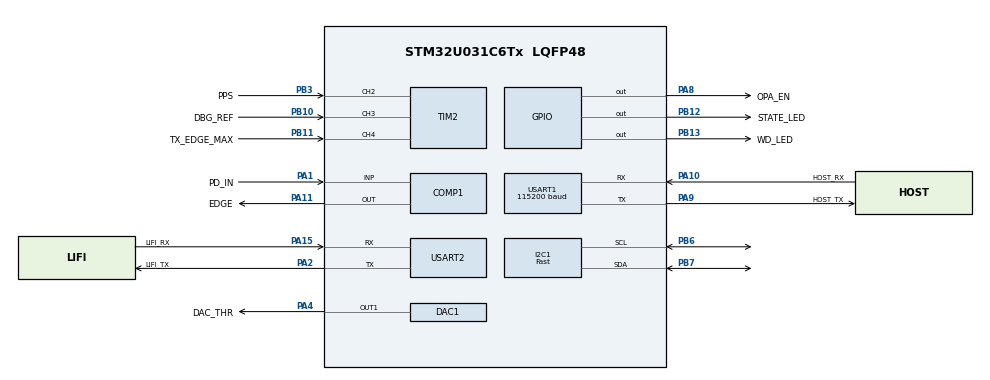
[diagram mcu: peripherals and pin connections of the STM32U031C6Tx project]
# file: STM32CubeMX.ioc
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ADC1.Channel-0\#ChannelRegularConversion=ADC_CHANNEL_5
ADC1.NbrOfConversionFlag=1
ADC1.Rank-0\#ChannelRegularConversion=1
ADC1.RankArg-0\#ChannelRegularConversion=ADC_REGULAR_RANK_1
ADC1.SamplingTime-0\#ChannelRegularConversion=ADC_SAMPLINGTIME_COMMON_1
ADC1.SamplingTimeCommon1=ADC_SAMPLETIME_39CYCLES_5
ADC1.SelectedChannel=ADC_CHANNEL_5
ADC1.master=1
COMP1.Hysteresis=COMP_HYSTERESIS_LOW
Dma.Request0=USART2_TX
Dma.Request1=USART1_TX
Dma.Request2=USART1_RX
Dma.Request3=USART2_RX
Dma.USART1_RX.2.Direction=DMA_PERIPH_TO_MEMORY
Dma.USART1_RX.2.EventEnable=DISABLE
Dma.USART1_RX.2.Instance=DMA1_Channel3
Dma.USART1_RX.2.MemDataAlignment=DMA_MDATAALIGN_BYTE
Dma.USART1_RX.2.MemInc=DMA_MINC_ENABLE
Dma.USART1_RX.2.Mode=DMA_CIRCULAR
Dma.USART1_RX.2.PeriphDataAlignment=DMA_PDATAALIGN_BYTE
Dma.USART1_RX.2.PeriphInc=DMA_PINC_DISABLE
Dma.USART1_RX.2.Polarity=HAL_DMAMUX_REQ_GEN_RISING
Dma.USART1_RX.2.Priority=DMA_PRIORITY_LOW
Dma.USART1_RX.2.RequestNumber=1
Dma.USART1_RX.2.SignalID=NONE
Dma.USART1_RX.2.SyncEnable=DISABLE
Dma.USART1_RX.2.SyncPolarity=HAL_DMAMUX_SYNC_NO_EVENT
Dma.USART1_RX.2.SyncRequestNumber=1
Dma.USART1_RX.2.SyncSignalID=NONE
Dma.USART1_TX.1.Direction=DMA_MEMORY_TO_PERIPH
Dma.USART1_TX.1.EventEnable=DISABLE
Dma.USART1_TX.1.Instance=DMA1_Channel2
Dma.USART1_TX.1.MemDataAlignment=DMA_MDATAALIGN_BYTE
Dma.USART1_TX.1.MemInc=DMA_MINC_ENABLE
Dma.USART1_TX.1.Mode=DMA_NORMAL
Dma.USART1_TX.1.PeriphDataAlignment=DMA_PDATAALIGN_BYTE
Dma.USART1_TX.1.PeriphInc=DMA_PINC_DISABLE
Dma.USART1_TX.1.Polarity=HAL_DMAMUX_REQ_GEN_RISING
Dma.USART1_TX.1.Priority=DMA_PRIORITY_LOW
Dma.USART1_TX.1.RequestNumber=1
Dma.USART1_TX.1.SignalID=NONE
Dma.USART1_TX.1.SyncEnable=DISABLE
Dma.USART1_TX.1.SyncPolarity=HAL_DMAMUX_SYNC_NO_EVENT
Dma.USART1_TX.1.SyncRequestNumber=1
Dma.USART1_TX.1.SyncSignalID=NONE
Dma.USART2_RX.3.Direction=DMA_PERIPH_TO_MEMORY
Dma.USART2_RX.3.EventEnable=DISABLE
Dma.USART2_RX.3.Instance=DMA1_Channel4
Dma.USART2_RX.3.MemDataAlignment=DMA_MDATAALIGN_BYTE
Dma.USART2_RX.3.MemInc=DMA_MINC_ENABLE
Dma.USART2_RX.3.Mode=DMA_CIRCULAR
Dma.USART2_RX.3.PeriphDataAlignment=DMA_PDATAALIGN_BYTE
Dma.USART2_RX.3.PeriphInc=DMA_PINC_DISABLE
Dma.USART2_RX.3.Polarity=HAL_DMAMUX_REQ_GEN_RISING
Dma.USART2_RX.3.Priority=DMA_PRIORITY_LOW
Dma.USART2_RX.3.RequestNumber=1
Dma.USART2_RX.3.SignalID=NONE
Dma.USART2_RX.3.SyncEnable=DISABLE
Dma.USART2_RX.3.SyncPolarity=HAL_DMAMUX_SYNC_NO_EVENT
Dma.USART2_RX.3.SyncRequestNumber=1
Dma.USART2_RX.3.SyncSignalID=NONE
Dma.USART2_TX.0.Direction=DMA_MEMORY_TO_PERIPH
Dma.USART2_TX.0.EventEnable=DISABLE
Dma.USART2_TX.0.Instance=DMA1_Channel1
Dma.USART2_TX.0.MemDataAlignment=DMA_MDATAALIGN_BYTE
Dma.USART2_TX.0.MemInc=DMA_MINC_ENABLE
Dma.USART2_TX.0.Mode=DMA_NORMAL
Dma.USART2_TX.0.PeriphDataAlignment=DMA_PDATAALIGN_BYTE
Dma.USART2_TX.0.PeriphInc=DMA_PINC_DISABLE
Dma.USART2_TX.0.Polarity=HAL_DMAMUX_REQ_GEN_RISING
Dma.USART2_TX.0.Priority=DMA_PRIORITY_LOW
Dma.USART2_TX.0.RequestNumber=1
Dma.USART2_TX.0.SignalID=NONE
Dma.USART2_TX.0.SyncEnable=DISABLE
Dma.USART2_TX.0.SyncPolarity=HAL_DMAMUX_SYNC_NO_EVENT
Dma.USART2_TX.0.SyncRequestNumber=1
Dma.USART2_TX.0.SyncSignalID=NONE
I2C1.I2C_Speed_Mode=I2C_Fast
I2C1.Timing=0x00200C28
Mcu.Family=STM32U0
Mcu.Name=STM32U031C6Tx
Mcu.Package=LQFP48
NVIC.DMA1_Ch4_7_DMAMUX_OVR_IRQn=true\:0\:0\:false\:false\:false\:false\:true\:true
NVIC.DMA1_Channel1_IRQn=true\:0\:0\:false\:false\:false\:false\:true\:true
NVIC.DMA1_Channel2_3_IRQn=true\:0\:0\:false\:false\:false\:false\:true\:true
NVIC.PriorityGroup=NVIC_PRIORITYGROUP_2
NVIC.TIM2_IRQn=true\:0\:0\:false\:false\:false\:true\:true\:true
NVIC.USART1_IRQn=true\:0\:0\:false\:false\:false\:true\:true\:true
NVIC.USART2_LPUART2_IRQn=true\:0\:0\:false\:false\:false\:true\:true\:true
PA1.GPIO_Label=PD_IN
PA1.Signal=SharedAnalog_PA1
PA10.GPIO_Label=HOST_RX
PA10.Mode=Asynchronous
PA10.Signal=USART1_RX
PA11\ [PA9].GPIO_Label=EDGE
PA11\ [PA9].Mode=ExternalOutput
PA11\ [PA9].Signal=COMP1_OUT
PA13\ (SWDIO).GPIO_Label=SWDIO
PA13\ (SWDIO).Mode=Serial_Wire
PA13\ (SWDIO).Signal=DEBUG_JTMS-SWDIO
PA14\ (SWCLK).GPIO_Label=SWCLK
PA14\ (SWCLK).Mode=Serial_Wire
PA14\ (SWCLK).Signal=DEBUG_JTCK-SWCLK
PA15.GPIO_Label=LIFI_RX
PA15.Mode=Asynchronous
PA15.Signal=USART2_RX
PA2.GPIO_Label=LIFI_TX
PA2.Mode=Asynchronous
PA2.Signal=USART2_TX
PA4.GPIO_Label=DAC_THR
PA4.Signal=COMP_DAC11_group
PA8.GPIO_Label=OPA_EN
PA8.PinState=GPIO_PIN_RESET
PA8.Signal=GPIO_Output
PA9.GPIO_Label=HOST_TX
PA9.Mode=Asynchronous
PA9.Signal=USART1_TX
PB10.GPIO_Label=DBG_REF
PB10.Signal=S_TIM2_CH3
PB11.GPIO_Label=TX_EDGE_MAX
PB11.Signal=S_TIM2_CH4
PB12.GPIO_Label=STATE_LED
PB12.Signal=GPIO_Output
PB13.GPIO_Label=WD_LED
PB13.Signal=GPIO_Output
PB3.GPIO_Label=PPS
PB3.Signal=S_TIM2_CH2
PB6.Mode=I2C
PB6.Signal=I2C1_SCL
PB7.Mode=I2C
PB7.Signal=I2C1_SDA
PF0-OSC_IN.GPIO_Label=OSC_IN
PF0-OSC_IN.Mode=HSE-External-Clock-Source
PF0-OSC_IN.Signal=RCC_OSC_IN
PF1-OSC_OUT.GPIO_Label=OSC_EN
PF1-OSC_OUT.Mode=OSC enable
PF1-OSC_OUT.Signal=RCC_OSC_EN
ProjectManager.HeapSize=0x0
ProjectManager.StackSize=0x400
ProjectManager.TargetToolchain=STM32CubeIDE
RCC.ADCFreq_Value=24000000
RCC.AHBFreq_Value=24000000
RCC.CortexFreq_Value=24000000
RCC.HCLKFreq_Value=24000000
RCC.HSE_VALUE=24000000
RCC.HSI48_VALUE=48000000
RCC.HSI_VALUE=16000000
RCC.LSE_VALUE=32768
RCC.MSI_VALUE=4000000
RCC.SYSCLKFreq_VALUE=24000000
RCC.SYSCLKSource=RCC_SYSCLKSOURCE_HSE
RCC.VCOOutputFreq_Value=64000000
SH.COMP_DAC11_group.0=DAC1_OUT1,DAC_OUT1_ExtAndInt
SH.S_TIM2_CH2.0=TIM2_CH2,Input_Capture2_from_TI2
SH.S_TIM2_CH3.0=TIM2_CH3,Input_Capture3_from_TI3
SH.S_TIM2_CH4.0=TIM2_CH4,Input_Capture4_from_TI4
SH.SharedAnalog_PA1.0=COMP1_INP,INP
SH.SharedAnalog_PA1.1=ADC1_IN5,IN5
TIM2.Channel-Input_Capture1_from_TI1_REMAP_TIM2=TIM_CHANNEL_1
TIM2.Channel-Input_Capture2_from_TI2=TIM_CHANNEL_2
TIM2.Channel-Input_Capture3_from_TI3=TIM_CHANNEL_3
TIM2.Channel-Input_Capture4_from_TI4=TIM_CHANNEL_4
TIM2.ICPolarity_CH1=TIM_INPUTCHANNELPOLARITY_BOTHEDGE
TIM2.ICPolarity_CH4=TIM_INPUTCHANNELPOLARITY_BOTHEDGE
USART1.BaudRate=115200
USART1.VirtualMode-Asynchronous=VM_ASYNC
USART2.RxPinLevelInvertParam=ADVFEATURE_RXINV_ENABLE
USART2.TxPinLevelInvertParam=ADVFEATURE_TXINV_ENABLE
USART2.VirtualMode-Asynchronous=VM_ASYNC
VP_COMP1_VS_DACOUT1.Mode=INM_DACOUT1
VP_PWR_VS_SECSignals.Mode=Security/Privilege
VP_TIM2_VS_ClockSourceINT.Mode=Internal
VP_TIM2_VS_NoInput1.Mode=Input_Capture1_from_TI1_REMAP_TIM2
board=custom

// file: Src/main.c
/* USER CODE BEGIN Header */
/**
  ******************************************************************************
  * @file           : main.c
  * @brief          : Main program body
  ******************************************************************************
  * @attention
  *
  * Copyright (c) 2026 STMicroelectronics.
  * All rights reserved.
  *
  * This software is licensed under terms that can be found in the LICENSE file
  * in the root directory of this software component.
  * If no LICENSE file comes with this software, it is provided AS-IS.
  *
  ******************************************************************************
  */
/* USER CODE END Header */
#include "main.h"

void SystemClock_Config(void);
static void MX_GPIO_Init(void);
static void MX_DMA_Init(void);
static void MX_USART1_UART_Init(void);
static void MX_COMP1_Init(void);
static void MX_USART2_UART_Init(void);
static void MX_ADC1_Init(void);
static void MX_DAC1_Init(void);
static void MX_TIM2_Init(void);
static void MX_I2C1_Init(void);
/* USER CODE BEGIN PFP */
extern int app_main(void);

/* USER CODE END PFP */

int main(void)
{

  /* MCU Configuration--------------------------------------------------------*/

  /* Reset of all peripherals, Initializes the Flash interface and the Systick. */
  LL_APB1_GRP1_EnableClock(LL_APB1_GRP1_PERIPH_PWR);
  LL_APB1_GRP2_EnableClock(LL_APB1_GRP2_PERIPH_SYSCFG);

  /* System interrupt init*/
  NVIC_SetPriorityGrouping(NVIC_PRIORITYGROUP_2);

  /* SysTick_IRQn interrupt configuration */
  NVIC_SetPriority(SysTick_IRQn, NVIC_EncodePriority(NVIC_GetPriorityGrouping(),3, 0));

  /* Initialize all configured peripherals */
  MX_GPIO_Init();
  MX_DMA_Init();
  MX_USART1_UART_Init();
  MX_COMP1_Init();
  MX_USART2_UART_Init();
  MX_ADC1_Init();
  MX_DAC1_Init();
  MX_TIM2_Init();
  MX_I2C1_Init();
  /* USER CODE BEGIN 2 */
  app_main();

  /* USER CODE END 2 */

  /* Infinite loop */
  while (1)
  {

  }
}

void SystemClock_Config(void)
{
  LL_FLASH_SetLatency(LL_FLASH_LATENCY_0);
  while(LL_FLASH_GetLatency() != LL_FLASH_LATENCY_0)
  {
  }

  LL_PWR_SetRegulVoltageScaling(LL_PWR_REGU_VOLTAGE_SCALE1);
  while (LL_PWR_IsActiveFlag_VOS() != 0)
  {
  }
  LL_RCC_HSE_EnableBypass();
  LL_RCC_HSE_Enable();

   /* Wait till HSE is ready */
  while(LL_RCC_HSE_IsReady() != 1)
  {
  }

  LL_RCC_SetSysClkSource(LL_RCC_SYS_CLKSOURCE_HSE);

   /* Wait till System clock is ready */
  while(LL_RCC_GetSysClkSource() != LL_RCC_SYS_CLKSOURCE_STATUS_HSE)
  {
  }

  LL_RCC_SetAHBPrescaler(LL_RCC_SYSCLK_DIV_1);
  LL_RCC_SetAPB1Prescaler(LL_RCC_APB1_DIV_1);

  LL_Init1msTick(24000000);

  LL_SetSystemCoreClock(24000000);
}

static void MX_ADC1_Init(void)
{

  LL_ADC_InitTypeDef ADC_InitStruct = {0};
  LL_ADC_REG_InitTypeDef ADC_REG_InitStruct = {0};

  LL_GPIO_InitTypeDef GPIO_InitStruct = {0};

  LL_RCC_SetADCClockSource(LL_RCC_ADC_CLKSOURCE_SYSCLK);

  /* Peripheral clock enable */
  LL_APB1_GRP2_EnableClock(LL_APB1_GRP2_PERIPH_ADC);

  LL_IOP_GRP1_EnableClock(LL_IOP_GRP1_PERIPH_GPIOA);
  /**ADC1 GPIO Configuration
  PA1   ------> ADC1_IN5
  */
  GPIO_InitStruct.Pin = PD_IN_Pin;
  GPIO_InitStruct.Mode = LL_GPIO_MODE_ANALOG;
  GPIO_InitStruct.Pull = LL_GPIO_PULL_NO;
  LL_GPIO_Init(PD_IN_GPIO_Port, &GPIO_InitStruct);

  /** Configure the global features of the ADC (Clock, Resolution, Data Alignment and number of conversion)
  */

   #define ADC_CHANNEL_CONF_RDY_TIMEOUT_MS ( 1U)
   #if (USE_TIMEOUT == 1)
   uint32_t Timeout ; /* Variable used for Timeout management */
   #endif /* USE_TIMEOUT */

  ADC_InitStruct.Clock = LL_ADC_CLOCK_SYNC_PCLK_DIV1;
  ADC_InitStruct.Resolution = LL_ADC_RESOLUTION_12B;
  ADC_InitStruct.DataAlignment = LL_ADC_DATA_ALIGN_RIGHT;
  ADC_InitStruct.LowPowerMode = LL_ADC_LP_MODE_NONE;
  LL_ADC_Init(ADC1, &ADC_InitStruct);
  LL_ADC_REG_SetSequencerConfigurable(ADC1, LL_ADC_REG_SEQ_CONFIGURABLE);

   /* Poll for ADC channel configuration ready */
   #if (USE_TIMEOUT == 1)
   Timeout = ADC_CHANNEL_CONF_RDY_TIMEOUT_MS;
   #endif /* USE_TIMEOUT */
   while (LL_ADC_IsActiveFlag_CCRDY(ADC1) == 0)
     {
   #if (USE_TIMEOUT == 1)
   /* Check Systick counter flag to decrement the time-out value */
   if (LL_SYSTICK_IsActiveCounterFlag())
     {
   if(Timeout-- == 0)
         {
   Error_Handler();
         }
     }
   #endif /* USE_TIMEOUT */
     }
   /* Clear flag ADC channel configuration ready */
   LL_ADC_ClearFlag_CCRDY(ADC1);
  ADC_REG_InitStruct.TriggerSource = LL_ADC_REG_TRIG_SOFTWARE;
  ADC_REG_InitStruct.SequencerLength = LL_ADC_REG_SEQ_SCAN_DISABLE;
  ADC_REG_InitStruct.SequencerDiscont = LL_ADC_REG_SEQ_DISCONT_DISABLE;
  ADC_REG_InitStruct.ContinuousMode = LL_ADC_REG_CONV_SINGLE;
  ADC_REG_InitStruct.DMATransfer = LL_ADC_REG_DMA_TRANSFER_NONE;
  ADC_REG_InitStruct.Overrun = LL_ADC_REG_OVR_DATA_PRESERVED;
  LL_ADC_REG_Init(ADC1, &ADC_REG_InitStruct);
  LL_ADC_SetOverSamplingScope(ADC1, LL_ADC_OVS_DISABLE);
  LL_ADC_SetTriggerFrequencyMode(ADC1, LL_ADC_TRIGGER_FREQ_HIGH);
  LL_ADC_SetSamplingTimeCommonChannels(ADC1, LL_ADC_SAMPLINGTIME_COMMON_1, LL_ADC_SAMPLINGTIME_39CYCLES_5);
  LL_ADC_SetSamplingTimeCommonChannels(ADC1, LL_ADC_SAMPLINGTIME_COMMON_2, LL_ADC_SAMPLINGTIME_1CYCLE_5);
  LL_ADC_DisableIT_EOC(ADC1);
  LL_ADC_DisableIT_EOS(ADC1);

   /* Enable ADC internal voltage regulator */
   LL_ADC_EnableInternalRegulator(ADC1);
   /* Delay for ADC internal voltage regulator stabilization. */
   /* Compute number of CPU cycles to wait for, from delay in us. */
   /* Note: Variable divided by 2 to compensate partially */
   /* CPU processing cycles (depends on compilation optimization). */
   /* Note: If system core clock frequency is below 200kHz, wait time */
   /* is only a few CPU processing cycles. */
   uint32_t wait_loop_index;
   wait_loop_index = ((LL_ADC_DELAY_INTERNAL_REGUL_STAB_US * (SystemCoreClock / (100000 * 2))) / 10);
   while(wait_loop_index != 0)
     {
   wait_loop_index--;
     }

  /** Configure Regular Channel
  */
  LL_ADC_REG_SetSequencerRanks(ADC1, LL_ADC_REG_RANK_1, LL_ADC_CHANNEL_5);

   /* Poll for ADC channel configuration ready */
   #if (USE_TIMEOUT == 1)
   Timeout = ADC_CHANNEL_CONF_RDY_TIMEOUT_MS;
   #endif /* USE_TIMEOUT */
   while (LL_ADC_IsActiveFlag_CCRDY(ADC1) == 0)
     {
   #if (USE_TIMEOUT == 1)
   /* Check Systick counter flag to decrement the time-out value */
   if (LL_SYSTICK_IsActiveCounterFlag())
     {
   if(Timeout-- == 0)
         {
   Error_Handler();
         }
     }
   #endif /* USE_TIMEOUT */
     }
   /* Clear flag ADC channel configuration ready */
   LL_ADC_ClearFlag_CCRDY(ADC1);
  LL_ADC_SetChannelSamplingTime(ADC1, LL_ADC_CHANNEL_5, LL_ADC_SAMPLINGTIME_COMMON_1);

}

static void MX_COMP1_Init(void)
{

  LL_COMP_InitTypeDef COMP_InitStruct = {0};

  LL_GPIO_InitTypeDef GPIO_InitStruct = {0};

  /* Peripheral clock enable */
  LL_APB1_GRP2_EnableClock(LL_APB1_GRP2_PERIPH_COMP);

  LL_IOP_GRP1_EnableClock(LL_IOP_GRP1_PERIPH_GPIOA);
  /**COMP1 GPIO Configuration
  PA1   ------> COMP1_INP
  PA11 [PA9]   ------> COMP1_OUT
  */
  GPIO_InitStruct.Pin = PD_IN_Pin;
  GPIO_InitStruct.Mode = LL_GPIO_MODE_ANALOG;
  GPIO_InitStruct.Pull = LL_GPIO_PULL_NO;
  LL_GPIO_Init(PD_IN_GPIO_Port, &GPIO_InitStruct);

  GPIO_InitStruct.Pin = EDGE_Pin;
  GPIO_InitStruct.Mode = LL_GPIO_MODE_ALTERNATE;
  GPIO_InitStruct.Speed = LL_GPIO_SPEED_FREQ_LOW;
  GPIO_InitStruct.OutputType = LL_GPIO_OUTPUT_PUSHPULL;
  GPIO_InitStruct.Pull = LL_GPIO_PULL_NO;
  GPIO_InitStruct.Alternate = LL_GPIO_AF_12;
  LL_GPIO_Init(EDGE_GPIO_Port, &GPIO_InitStruct);

  COMP_InitStruct.InputPlus = LL_COMP_INPUT_PLUS_IO3;
  COMP_InitStruct.InputMinus = LL_COMP_INPUT_MINUS_DAC1_CH1;
  COMP_InitStruct.InputHysteresis = LL_COMP_HYSTERESIS_LOW;
  COMP_InitStruct.OutputPolarity = LL_COMP_OUTPUTPOL_NONINVERTED;
  COMP_InitStruct.OutputBlankingSource = LL_COMP_BLANKINGSRC_NONE;
  LL_COMP_Init(COMP1, &COMP_InitStruct);
  LL_COMP_SetPowerMode(COMP1, LL_COMP_POWERMODE_HIGHSPEED);

  /* Wait loop initialization and execution */
  /* Note: Variable divided by 2 to compensate partially CPU processing cycles */
  __IO uint32_t wait_loop_index = 0;
  wait_loop_index = (LL_COMP_DELAY_VOLTAGE_SCALER_STAB_US * (SystemCoreClock / (1000000 * 2)));
  while(wait_loop_index != 0)
  {
    wait_loop_index--;
  }
  LL_EXTI_DisableEvent_0_31(LL_EXTI_LINE_17);
  LL_EXTI_DisableIT_0_31(LL_EXTI_LINE_17);

}

static void MX_DAC1_Init(void)
{

  LL_DAC_InitTypeDef DAC_InitStruct = {0};

  LL_GPIO_InitTypeDef GPIO_InitStruct = {0};

  /* Peripheral clock enable */
  LL_APB1_GRP1_EnableClock(LL_APB1_GRP1_PERIPH_DAC1);

  LL_IOP_GRP1_EnableClock(LL_IOP_GRP1_PERIPH_GPIOA);
  /**DAC1 GPIO Configuration
  PA4   ------> DAC1_OUT1
  */
  GPIO_InitStruct.Pin = DAC_THR_Pin;
  GPIO_InitStruct.Mode = LL_GPIO_MODE_ANALOG;
  GPIO_InitStruct.Pull = LL_GPIO_PULL_NO;
  LL_GPIO_Init(DAC_THR_GPIO_Port, &GPIO_InitStruct);

  /** DAC channel OUT1 config
  */
  DAC_InitStruct.TriggerSource = LL_DAC_TRIG_SOFTWARE;
  DAC_InitStruct.WaveAutoGeneration = LL_DAC_WAVE_AUTO_GENERATION_NONE;
  DAC_InitStruct.OutputBuffer = LL_DAC_OUTPUT_BUFFER_ENABLE;
  DAC_InitStruct.OutputConnection = LL_DAC_OUTPUT_CONNECT_INTERNAL;
  DAC_InitStruct.OutputMode = LL_DAC_OUTPUT_MODE_NORMAL;
  LL_DAC_Init(DAC1, LL_DAC_CHANNEL_1, &DAC_InitStruct);
  LL_DAC_DisableTrigger(DAC1, LL_DAC_CHANNEL_1);

}

static void MX_I2C1_Init(void)
{

  LL_I2C_InitTypeDef I2C_InitStruct = {0};

  LL_GPIO_InitTypeDef GPIO_InitStruct = {0};

  LL_RCC_SetI2CClockSource(LL_RCC_I2C1_CLKSOURCE_PCLK1);

  LL_IOP_GRP1_EnableClock(LL_IOP_GRP1_PERIPH_GPIOB);
  /**I2C1 GPIO Configuration
  PB6   ------> I2C1_SCL
  PB7   ------> I2C1_SDA
  */
  GPIO_InitStruct.Pin = LL_GPIO_PIN_6|LL_GPIO_PIN_7;
  GPIO_InitStruct.Mode = LL_GPIO_MODE_ALTERNATE;
  GPIO_InitStruct.Speed = LL_GPIO_SPEED_FREQ_LOW;
  GPIO_InitStruct.OutputType = LL_GPIO_OUTPUT_OPENDRAIN;
  GPIO_InitStruct.Pull = LL_GPIO_PULL_NO;
  GPIO_InitStruct.Alternate = LL_GPIO_AF_4;
  LL_GPIO_Init(GPIOB, &GPIO_InitStruct);

  /* Peripheral clock enable */
  LL_APB1_GRP1_EnableClock(LL_APB1_GRP1_PERIPH_I2C1);

  /** I2C Initialization
  */
  LL_I2C_EnableAutoEndMode(I2C1);
  LL_I2C_DisableOwnAddress2(I2C1);
  LL_I2C_DisableGeneralCall(I2C1);
  LL_I2C_EnableClockStretching(I2C1);
  I2C_InitStruct.Timing = 0x00200C28;
  I2C_InitStruct.AnalogFilter = LL_I2C_ANALOGFILTER_ENABLE;
  I2C_InitStruct.DigitalFilter = 0;
  I2C_InitStruct.OwnAddress1 = 0;
  I2C_InitStruct.TypeAcknowledge = LL_I2C_ACK;
  I2C_InitStruct.OwnAddrSize = LL_I2C_OWNADDRESS1_7BIT;
  LL_I2C_Init(I2C1, &I2C_InitStruct);
  LL_I2C_SetOwnAddress2(I2C1, 0, LL_I2C_OWNADDRESS2_NOMASK);

}

static void MX_TIM2_Init(void)
{

  LL_TIM_InitTypeDef TIM_InitStruct = {0};

  LL_GPIO_InitTypeDef GPIO_InitStruct = {0};

  /* Peripheral clock enable */
  LL_APB1_GRP1_EnableClock(LL_APB1_GRP1_PERIPH_TIM2);

  LL_IOP_GRP1_EnableClock(LL_IOP_GRP1_PERIPH_GPIOB);
  /**TIM2 GPIO Configuration
  PB10   ------> TIM2_CH3
  PB11   ------> TIM2_CH4
  PB3   ------> TIM2_CH2
  */
  GPIO_InitStruct.Pin = DBG_REF_Pin|TX_EDGE_MAX_Pin|PPS_Pin;
  GPIO_InitStruct.Mode = LL_GPIO_MODE_ALTERNATE;
  GPIO_InitStruct.Speed = LL_GPIO_SPEED_FREQ_LOW;
  GPIO_InitStruct.OutputType = LL_GPIO_OUTPUT_PUSHPULL;
  GPIO_InitStruct.Pull = LL_GPIO_PULL_NO;
  GPIO_InitStruct.Alternate = LL_GPIO_AF_1;
  LL_GPIO_Init(GPIOB, &GPIO_InitStruct);

  /* TIM2 interrupt Init */
  NVIC_SetPriority(TIM2_IRQn, NVIC_EncodePriority(NVIC_GetPriorityGrouping(),0, 0));
  NVIC_EnableIRQ(TIM2_IRQn);

  TIM_InitStruct.Prescaler = 0;
  TIM_InitStruct.CounterMode = LL_TIM_COUNTERMODE_UP;
  TIM_InitStruct.Autoreload = 4294967295;
  TIM_InitStruct.ClockDivision = LL_TIM_CLOCKDIVISION_DIV1;
  LL_TIM_Init(TIM2, &TIM_InitStruct);
  LL_TIM_DisableARRPreload(TIM2);
  LL_TIM_SetClockSource(TIM2, LL_TIM_CLOCKSOURCE_INTERNAL);
  LL_TIM_SetTriggerOutput(TIM2, LL_TIM_TRGO_RESET);
  LL_TIM_DisableMasterSlaveMode(TIM2);
  LL_TIM_IC_SetActiveInput(TIM2, LL_TIM_CHANNEL_CH1, LL_TIM_ACTIVEINPUT_DIRECTTI);
  LL_TIM_IC_SetPrescaler(TIM2, LL_TIM_CHANNEL_CH1, LL_TIM_ICPSC_DIV1);
  LL_TIM_IC_SetFilter(TIM2, LL_TIM_CHANNEL_CH1, LL_TIM_IC_FILTER_FDIV1);
  LL_TIM_IC_SetPolarity(TIM2, LL_TIM_CHANNEL_CH1, LL_TIM_IC_POLARITY_BOTHEDGE);
  LL_TIM_SetRemap(TIM2, LL_TIM_TIM2_TI1_RMP_COMP1);
  LL_TIM_IC_SetActiveInput(TIM2, LL_TIM_CHANNEL_CH2, LL_TIM_ACTIVEINPUT_DIRECTTI);
  LL_TIM_IC_SetPrescaler(TIM2, LL_TIM_CHANNEL_CH2, LL_TIM_ICPSC_DIV1);
  LL_TIM_IC_SetFilter(TIM2, LL_TIM_CHANNEL_CH2, LL_TIM_IC_FILTER_FDIV1);
  LL_TIM_IC_SetPolarity(TIM2, LL_TIM_CHANNEL_CH2, LL_TIM_IC_POLARITY_RISING);
  LL_TIM_IC_SetActiveInput(TIM2, LL_TIM_CHANNEL_CH3, LL_TIM_ACTIVEINPUT_DIRECTTI);
  LL_TIM_IC_SetPrescaler(TIM2, LL_TIM_CHANNEL_CH3, LL_TIM_ICPSC_DIV1);
  LL_TIM_IC_SetFilter(TIM2, LL_TIM_CHANNEL_CH3, LL_TIM_IC_FILTER_FDIV1);
  LL_TIM_IC_SetPolarity(TIM2, LL_TIM_CHANNEL_CH3, LL_TIM_IC_POLARITY_RISING);
  LL_TIM_IC_SetActiveInput(TIM2, LL_TIM_CHANNEL_CH4, LL_TIM_ACTIVEINPUT_DIRECTTI);
  LL_TIM_IC_SetPrescaler(TIM2, LL_TIM_CHANNEL_CH4, LL_TIM_ICPSC_DIV1);
  LL_TIM_IC_SetFilter(TIM2, LL_TIM_CHANNEL_CH4, LL_TIM_IC_FILTER_FDIV1);
  LL_TIM_IC_SetPolarity(TIM2, LL_TIM_CHANNEL_CH4, LL_TIM_IC_POLARITY_BOTHEDGE);

}

static void MX_USART1_UART_Init(void)
{

  LL_USART_InitTypeDef USART_InitStruct = {0};

  LL_GPIO_InitTypeDef GPIO_InitStruct = {0};

  LL_RCC_SetUSARTClockSource(LL_RCC_USART1_CLKSOURCE_PCLK1);

  /* Peripheral clock enable */
  LL_APB1_GRP2_EnableClock(LL_APB1_GRP2_PERIPH_USART1);

  LL_IOP_GRP1_EnableClock(LL_IOP_GRP1_PERIPH_GPIOA);
  /**USART1 GPIO Configuration
  PA9   ------> USART1_TX
  PA10   ------> USART1_RX
  */
  GPIO_InitStruct.Pin = HOST_TX_Pin|HOST_RX_Pin;
  GPIO_InitStruct.Mode = LL_GPIO_MODE_ALTERNATE;
  GPIO_InitStruct.Speed = LL_GPIO_SPEED_FREQ_LOW;
  GPIO_InitStruct.OutputType = LL_GPIO_OUTPUT_PUSHPULL;
  GPIO_InitStruct.Pull = LL_GPIO_PULL_NO;
  GPIO_InitStruct.Alternate = LL_GPIO_AF_7;
  LL_GPIO_Init(GPIOA, &GPIO_InitStruct);

  /* USART1 DMA Init */

  /* USART1_TX Init */
  LL_DMA_SetPeriphRequest(DMA1, LL_DMA_CHANNEL_2, LL_DMAMUX_REQ_USART1_TX);

  LL_DMA_SetDataTransferDirection(DMA1, LL_DMA_CHANNEL_2, LL_DMA_DIRECTION_MEMORY_TO_PERIPH);

  LL_DMA_SetChannelPriorityLevel(DMA1, LL_DMA_CHANNEL_2, LL_DMA_PRIORITY_LOW);

  LL_DMA_SetMode(DMA1, LL_DMA_CHANNEL_2, LL_DMA_MODE_NORMAL);

  LL_DMA_SetPeriphIncMode(DMA1, LL_DMA_CHANNEL_2, LL_DMA_PERIPH_NOINCREMENT);

  LL_DMA_SetMemoryIncMode(DMA1, LL_DMA_CHANNEL_2, LL_DMA_MEMORY_INCREMENT);

  LL_DMA_SetPeriphSize(DMA1, LL_DMA_CHANNEL_2, LL_DMA_PDATAALIGN_BYTE);

  LL_DMA_SetMemorySize(DMA1, LL_DMA_CHANNEL_2, LL_DMA_MDATAALIGN_BYTE);

  /* USART1_RX Init */
  LL_DMA_SetPeriphRequest(DMA1, LL_DMA_CHANNEL_3, LL_DMAMUX_REQ_USART1_RX);

  LL_DMA_SetDataTransferDirection(DMA1, LL_DMA_CHANNEL_3, LL_DMA_DIRECTION_PERIPH_TO_MEMORY);

  LL_DMA_SetChannelPriorityLevel(DMA1, LL_DMA_CHANNEL_3, LL_DMA_PRIORITY_LOW);

  LL_DMA_SetMode(DMA1, LL_DMA_CHANNEL_3, LL_DMA_MODE_CIRCULAR);

  LL_DMA_SetPeriphIncMode(DMA1, LL_DMA_CHANNEL_3, LL_DMA_PERIPH_NOINCREMENT);

  LL_DMA_SetMemoryIncMode(DMA1, LL_DMA_CHANNEL_3, LL_DMA_MEMORY_INCREMENT);

  LL_DMA_SetPeriphSize(DMA1, LL_DMA_CHANNEL_3, LL_DMA_PDATAALIGN_BYTE);

  LL_DMA_SetMemorySize(DMA1, LL_DMA_CHANNEL_3, LL_DMA_MDATAALIGN_BYTE);

  /* USART1 interrupt Init */
  NVIC_SetPriority(USART1_IRQn, NVIC_EncodePriority(NVIC_GetPriorityGrouping(),0, 0));
  NVIC_EnableIRQ(USART1_IRQn);

  USART_InitStruct.PrescalerValue = LL_USART_PRESCALER_DIV1;
  USART_InitStruct.BaudRate = 115200;
  USART_InitStruct.DataWidth = LL_USART_DATAWIDTH_8B;
  USART_InitStruct.StopBits = LL_USART_STOPBITS_1;
  USART_InitStruct.Parity = LL_USART_PARITY_NONE;
  USART_InitStruct.TransferDirection = LL_USART_DIRECTION_TX_RX;
  USART_InitStruct.HardwareFlowControl = LL_USART_HWCONTROL_NONE;
  USART_InitStruct.OverSampling = LL_USART_OVERSAMPLING_16;
  LL_USART_Init(USART1, &USART_InitStruct);
  LL_USART_SetTXFIFOThreshold(USART1, LL_USART_FIFOTHRESHOLD_1_8);
  LL_USART_SetRXFIFOThreshold(USART1, LL_USART_FIFOTHRESHOLD_1_8);
  LL_USART_DisableFIFO(USART1);
  LL_USART_ConfigAsyncMode(USART1);
  LL_USART_Enable(USART1);

}

static void MX_USART2_UART_Init(void)
{

  LL_USART_InitTypeDef USART_InitStruct = {0};

  LL_GPIO_InitTypeDef GPIO_InitStruct = {0};

  LL_RCC_SetUSARTClockSource(LL_RCC_USART2_CLKSOURCE_PCLK1);

  /* Peripheral clock enable */
  LL_APB1_GRP1_EnableClock(LL_APB1_GRP1_PERIPH_USART2);

  LL_IOP_GRP1_EnableClock(LL_IOP_GRP1_PERIPH_GPIOA);
  /**USART2 GPIO Configuration
  PA2   ------> USART2_TX
  PA15   ------> USART2_RX
  */
  GPIO_InitStruct.Pin = LIFI_TX_Pin;
  GPIO_InitStruct.Mode = LL_GPIO_MODE_ALTERNATE;
  GPIO_InitStruct.Speed = LL_GPIO_SPEED_FREQ_LOW;
  GPIO_InitStruct.OutputType = LL_GPIO_OUTPUT_PUSHPULL;
  GPIO_InitStruct.Pull = LL_GPIO_PULL_NO;
  GPIO_InitStruct.Alternate = LL_GPIO_AF_7;
  LL_GPIO_Init(LIFI_TX_GPIO_Port, &GPIO_InitStruct);

  GPIO_InitStruct.Pin = LIFI_RX_Pin;
  GPIO_InitStruct.Mode = LL_GPIO_MODE_ALTERNATE;
  GPIO_InitStruct.Speed = LL_GPIO_SPEED_FREQ_LOW;
  GPIO_InitStruct.OutputType = LL_GPIO_OUTPUT_PUSHPULL;
  GPIO_InitStruct.Pull = LL_GPIO_PULL_NO;
  GPIO_InitStruct.Alternate = LL_GPIO_AF_3;
  LL_GPIO_Init(LIFI_RX_GPIO_Port, &GPIO_InitStruct);

  /* USART2 DMA Init */

  /* USART2_TX Init */
  LL_DMA_SetPeriphRequest(DMA1, LL_DMA_CHANNEL_1, LL_DMAMUX_REQ_USART2_TX);

  LL_DMA_SetDataTransferDirection(DMA1, LL_DMA_CHANNEL_1, LL_DMA_DIRECTION_MEMORY_TO_PERIPH);

  LL_DMA_SetChannelPriorityLevel(DMA1, LL_DMA_CHANNEL_1, LL_DMA_PRIORITY_LOW);

  LL_DMA_SetMode(DMA1, LL_DMA_CHANNEL_1, LL_DMA_MODE_NORMAL);

  LL_DMA_SetPeriphIncMode(DMA1, LL_DMA_CHANNEL_1, LL_DMA_PERIPH_NOINCREMENT);

  LL_DMA_SetMemoryIncMode(DMA1, LL_DMA_CHANNEL_1, LL_DMA_MEMORY_INCREMENT);

  LL_DMA_SetPeriphSize(DMA1, LL_DMA_CHANNEL_1, LL_DMA_PDATAALIGN_BYTE);

  LL_DMA_SetMemorySize(DMA1, LL_DMA_CHANNEL_1, LL_DMA_MDATAALIGN_BYTE);

  /* USART2_RX Init */
  LL_DMA_SetPeriphRequest(DMA1, LL_DMA_CHANNEL_4, LL_DMAMUX_REQ_USART2_RX);

  LL_DMA_SetDataTransferDirection(DMA1, LL_DMA_CHANNEL_4, LL_DMA_DIRECTION_PERIPH_TO_MEMORY);

  LL_DMA_SetChannelPriorityLevel(DMA1, LL_DMA_CHANNEL_4, LL_DMA_PRIORITY_LOW);

  LL_DMA_SetMode(DMA1, LL_DMA_CHANNEL_4, LL_DMA_MODE_CIRCULAR);

  LL_DMA_SetPeriphIncMode(DMA1, LL_DMA_CHANNEL_4, LL_DMA_PERIPH_NOINCREMENT);

  LL_DMA_SetMemoryIncMode(DMA1, LL_DMA_CHANNEL_4, LL_DMA_MEMORY_INCREMENT);

  LL_DMA_SetPeriphSize(DMA1, LL_DMA_CHANNEL_4, LL_DMA_PDATAALIGN_BYTE);

  LL_DMA_SetMemorySize(DMA1, LL_DMA_CHANNEL_4, LL_DMA_MDATAALIGN_BYTE);

  /* USART2 interrupt Init */
  NVIC_SetPriority(USART2_LPUART2_IRQn, NVIC_EncodePriority(NVIC_GetPriorityGrouping(),0, 0));
  NVIC_EnableIRQ(USART2_LPUART2_IRQn);

  USART_InitStruct.PrescalerValue = LL_USART_PRESCALER_DIV1;
  USART_InitStruct.BaudRate = 115200;
  USART_InitStruct.DataWidth = LL_USART_DATAWIDTH_8B;
  USART_InitStruct.StopBits = LL_USART_STOPBITS_1;
  USART_InitStruct.Parity = LL_USART_PARITY_NONE;
  USART_InitStruct.TransferDirection = LL_USART_DIRECTION_TX_RX;
  USART_InitStruct.HardwareFlowControl = LL_USART_HWCONTROL_NONE;
  USART_InitStruct.OverSampling = LL_USART_OVERSAMPLING_16;
  LL_USART_Init(USART2, &USART_InitStruct);
  LL_USART_SetTXFIFOThreshold(USART2, LL_USART_FIFOTHRESHOLD_1_8);
  LL_USART_SetRXFIFOThreshold(USART2, LL_USART_FIFOTHRESHOLD_1_8);
  LL_USART_DisableFIFO(USART2);
  LL_USART_SetRXPinLevel(USART2, LL_USART_RXPIN_LEVEL_INVERTED);
  LL_USART_SetTXPinLevel(USART2, LL_USART_TXPIN_LEVEL_INVERTED);
  LL_USART_ConfigAsyncMode(USART2);
  LL_USART_Enable(USART2);

}

static void MX_DMA_Init(void)
{

  /* Init with LL driver */
  /* DMA controller clock enable */
  LL_AHB1_GRP1_EnableClock(LL_AHB1_GRP1_PERIPH_DMA1);

  /* DMA interrupt init */
  /* DMA1_Channel1_IRQn interrupt configuration */
  NVIC_SetPriority(DMA1_Channel1_IRQn, NVIC_EncodePriority(NVIC_GetPriorityGrouping(),0, 0));
  NVIC_EnableIRQ(DMA1_Channel1_IRQn);
  /* DMA1_Channel2_3_IRQn interrupt configuration */
  NVIC_SetPriority(DMA1_Channel2_3_IRQn, NVIC_EncodePriority(NVIC_GetPriorityGrouping(),0, 0));
  NVIC_EnableIRQ(DMA1_Channel2_3_IRQn);
  /* DMA1_Ch4_7_DMAMUX_OVR_IRQn interrupt configuration */
  NVIC_SetPriority(DMA1_Ch4_7_DMAMUX_OVR_IRQn, NVIC_EncodePriority(NVIC_GetPriorityGrouping(),0, 0));
  NVIC_EnableIRQ(DMA1_Ch4_7_DMAMUX_OVR_IRQn);

}

static void MX_GPIO_Init(void)
{
  LL_GPIO_InitTypeDef GPIO_InitStruct = {0};

  /* GPIO Ports Clock Enable */
  LL_IOP_GRP1_EnableClock(LL_IOP_GRP1_PERIPH_GPIOC);
  LL_IOP_GRP1_EnableClock(LL_IOP_GRP1_PERIPH_GPIOF);
  LL_IOP_GRP1_EnableClock(LL_IOP_GRP1_PERIPH_GPIOA);
  LL_IOP_GRP1_EnableClock(LL_IOP_GRP1_PERIPH_GPIOB);

  /**/
  LL_GPIO_ResetOutputPin(GPIOB, STATE_LED_Pin|WD_LED_Pin);

  /**/
  LL_GPIO_ResetOutputPin(OPA_EN_GPIO_Port, OPA_EN_Pin);

  /**/
  GPIO_InitStruct.Pin = LL_GPIO_PIN_13|LL_GPIO_PIN_14|LL_GPIO_PIN_15;
  GPIO_InitStruct.Mode = LL_GPIO_MODE_ANALOG;
  GPIO_InitStruct.Pull = LL_GPIO_PULL_NO;
  LL_GPIO_Init(GPIOC, &GPIO_InitStruct);

  /**/
  GPIO_InitStruct.Pin = OSC_EN_Pin;
  GPIO_InitStruct.Mode = LL_GPIO_MODE_ALTERNATE;
  GPIO_InitStruct.Speed = LL_GPIO_SPEED_FREQ_LOW;
  GPIO_InitStruct.OutputType = LL_GPIO_OUTPUT_PUSHPULL;
  GPIO_InitStruct.Pull = LL_GPIO_PULL_NO;
  GPIO_InitStruct.Alternate = GPIO_AF0_RCC;
  LL_GPIO_Init(OSC_EN_GPIO_Port, &GPIO_InitStruct);

  /**/
  GPIO_InitStruct.Pin = LL_GPIO_PIN_2|LL_GPIO_PIN_3;
  GPIO_InitStruct.Mode = LL_GPIO_MODE_ANALOG;
  GPIO_InitStruct.Pull = LL_GPIO_PULL_NO;
  LL_GPIO_Init(GPIOF, &GPIO_InitStruct);

  /**/
  GPIO_InitStruct.Pin = LL_GPIO_PIN_0|LL_GPIO_PIN_3|LL_GPIO_PIN_5|LL_GPIO_PIN_6
                          |LL_GPIO_PIN_7|LL_GPIO_PIN_12;
  GPIO_InitStruct.Mode = LL_GPIO_MODE_ANALOG;
  GPIO_InitStruct.Pull = LL_GPIO_PULL_NO;
  LL_GPIO_Init(GPIOA, &GPIO_InitStruct);

  /**/
  GPIO_InitStruct.Pin = LL_GPIO_PIN_0|LL_GPIO_PIN_1|LL_GPIO_PIN_2|LL_GPIO_PIN_14
                          |LL_GPIO_PIN_15|LL_GPIO_PIN_4|LL_GPIO_PIN_5|LL_GPIO_PIN_8
                          |LL_GPIO_PIN_9;
  GPIO_InitStruct.Mode = LL_GPIO_MODE_ANALOG;
  GPIO_InitStruct.Pull = LL_GPIO_PULL_NO;
  LL_GPIO_Init(GPIOB, &GPIO_InitStruct);

  /**/
  GPIO_InitStruct.Pin = STATE_LED_Pin|WD_LED_Pin;
  GPIO_InitStruct.Mode = LL_GPIO_MODE_OUTPUT;
  GPIO_InitStruct.Speed = LL_GPIO_SPEED_FREQ_LOW;
  GPIO_InitStruct.OutputType = LL_GPIO_OUTPUT_PUSHPULL;
  GPIO_InitStruct.Pull = LL_GPIO_PULL_NO;
  LL_GPIO_Init(GPIOB, &GPIO_InitStruct);

  /**/
  GPIO_InitStruct.Pin = OPA_EN_Pin;
  GPIO_InitStruct.Mode = LL_GPIO_MODE_OUTPUT;
  GPIO_InitStruct.Speed = LL_GPIO_SPEED_FREQ_LOW;
  GPIO_InitStruct.OutputType = LL_GPIO_OUTPUT_PUSHPULL;
  GPIO_InitStruct.Pull = LL_GPIO_PULL_NO;
  LL_GPIO_Init(OPA_EN_GPIO_Port, &GPIO_InitStruct);

}

void Error_Handler(void)
{
  __disable_irq();
  while (1)
  {
  }
}
